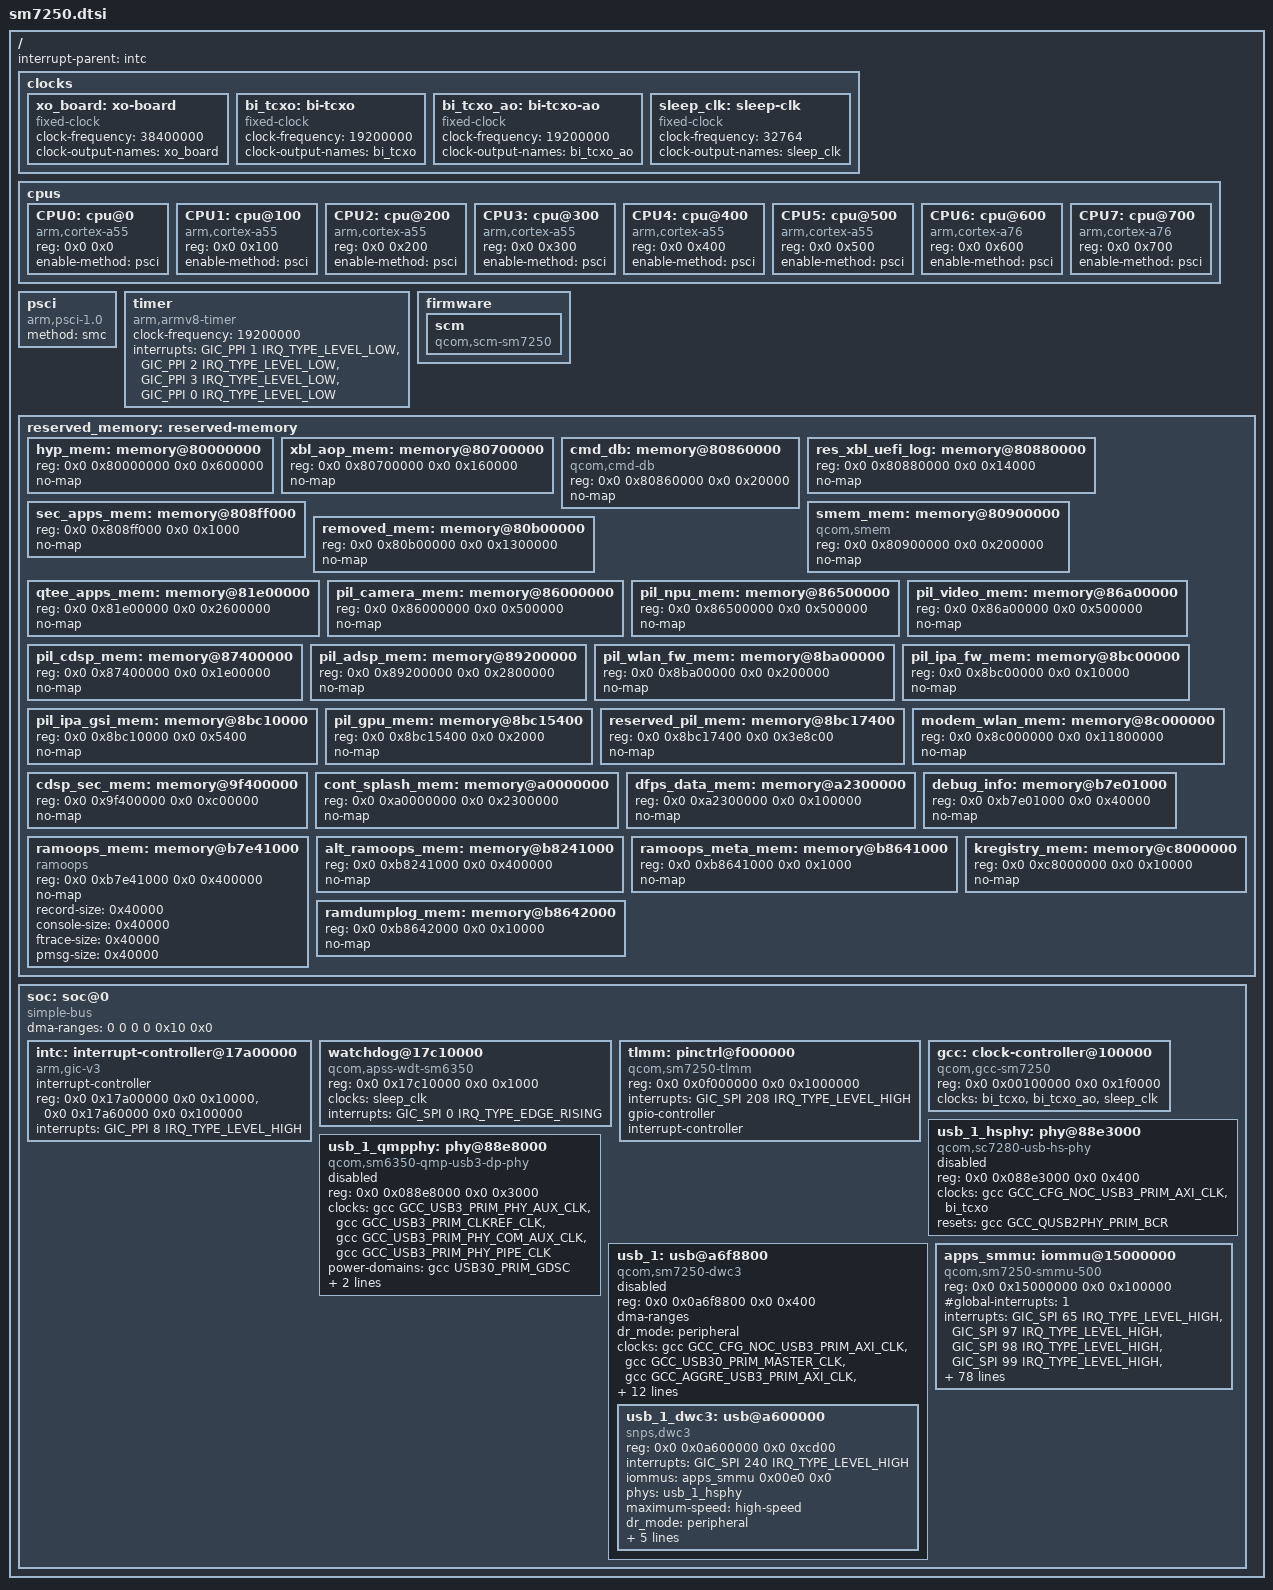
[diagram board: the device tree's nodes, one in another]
// SPDX-License-Identifier: BSD-3-Clause
/*
 * Copyright (c) 2026, Yurii Bishchuk
 * Base Device Tree Source for Qualcomm SM7250 (Snapdragon 765G / Lito)
 */

#include <dt-bindings/interrupt-controller/arm-gic.h>
#include <dt-bindings/clock/qcom,sm7250-gcc.h>
#include <dt-bindings/clock/qcom,rpmh.h>
#include <dt-bindings/power/qcom-rpmpd.h>
#include <dt-bindings/gpio/gpio.h>
#include <dt-bindings/phy/phy-qcom-qmp.h>

/ {
	interrupt-parent = <&intc>;
	#address-cells = <2>;
	#size-cells = <2>;

	clocks {
		xo_board: xo-board {
			compatible = "fixed-clock";
			#clock-cells = <0>;
			clock-frequency = <38400000>;
			clock-output-names = "xo_board";
		};

		bi_tcxo: bi-tcxo {
			compatible = "fixed-clock";
			#clock-cells = <0>;
			clock-frequency = <19200000>;
			clock-output-names = "bi_tcxo";
		};

		bi_tcxo_ao: bi-tcxo-ao {
			compatible = "fixed-clock";
			#clock-cells = <0>;
			clock-frequency = <19200000>;
			clock-output-names = "bi_tcxo_ao";
		};

		sleep_clk: sleep-clk {
			compatible = "fixed-clock";
			#clock-cells = <0>;
			clock-frequency = <32764>;
			clock-output-names = "sleep_clk";
		};
	};

	cpus {
		#address-cells = <2>;
		#size-cells = <0>;

		CPU0: cpu@0 {
			device_type = "cpu";
			compatible = "arm,cortex-a55";
			reg = <0x0 0x0>;
			enable-method = "psci";
		};

		CPU1: cpu@100 {
			device_type = "cpu";
			compatible = "arm,cortex-a55";
			reg = <0x0 0x100>;
			enable-method = "psci";
		};

		CPU2: cpu@200 {
			device_type = "cpu";
			compatible = "arm,cortex-a55";
			reg = <0x0 0x200>;
			enable-method = "psci";
		};

		CPU3: cpu@300 {
			device_type = "cpu";
			compatible = "arm,cortex-a55";
			reg = <0x0 0x300>;
			enable-method = "psci";
		};

		CPU4: cpu@400 {
			device_type = "cpu";
			compatible = "arm,cortex-a55";
			reg = <0x0 0x400>;
			enable-method = "psci";
		};

		CPU5: cpu@500 {
			device_type = "cpu";
			compatible = "arm,cortex-a55";
			reg = <0x0 0x500>;
			enable-method = "psci";
		};

		CPU6: cpu@600 {
			device_type = "cpu";
			compatible = "arm,cortex-a76";
			reg = <0x0 0x600>;
			enable-method = "psci";
		};

		CPU7: cpu@700 {
			device_type = "cpu";
			compatible = "arm,cortex-a76";
			reg = <0x0 0x700>;
			enable-method = "psci";
		};
	};

	psci {
		compatible = "arm,psci-1.0";
		method = "smc";
	};

	timer {
		compatible = "arm,armv8-timer";
		clock-frequency = <19200000>;
		interrupts = <GIC_PPI 1 IRQ_TYPE_LEVEL_LOW>,
			     <GIC_PPI 2 IRQ_TYPE_LEVEL_LOW>,
			     <GIC_PPI 3 IRQ_TYPE_LEVEL_LOW>,
			     <GIC_PPI 0 IRQ_TYPE_LEVEL_LOW>;
	};

	firmware {
		scm: scm {
			compatible = "qcom,scm-sm7250", "qcom,scm";
			#reset-cells = <1>;
		};
	};

	reserved_memory: reserved-memory {
		#address-cells = <2>;
		#size-cells = <2>;
		ranges;

		hyp_mem: memory@80000000 {
			reg = <0x0 0x80000000 0x0 0x600000>;
			no-map;
		};

		xbl_aop_mem: memory@80700000 {
			reg = <0x0 0x80700000 0x0 0x160000>;
			no-map;
		};

		cmd_db: memory@80860000 {
			compatible = "qcom,cmd-db";
			reg = <0x0 0x80860000 0x0 0x20000>;
			no-map;
		};

		res_xbl_uefi_log: memory@80880000 {
			reg = <0x0 0x80880000 0x0 0x14000>;
			no-map;
		};

		sec_apps_mem: memory@808ff000 {
			reg = <0x0 0x808ff000 0x0 0x1000>;
			no-map;
		};

		smem_mem: memory@80900000 {
			compatible = "qcom,smem";
			reg = <0x0 0x80900000 0x0 0x200000>;
			no-map;
		};

		removed_mem: memory@80b00000 {
			reg = <0x0 0x80b00000 0x0 0x1300000>;
			no-map;
		};

		qtee_apps_mem: memory@81e00000 {
			reg = <0x0 0x81e00000 0x0 0x2600000>;
			no-map;
		};

		pil_camera_mem: memory@86000000 {
			reg = <0x0 0x86000000 0x0 0x500000>;
			no-map;
		};

		pil_npu_mem: memory@86500000 {
			reg = <0x0 0x86500000 0x0 0x500000>;
			no-map;
		};

		pil_video_mem: memory@86a00000 {
			reg = <0x0 0x86a00000 0x0 0x500000>;
			no-map;
		};

		pil_cdsp_mem: memory@87400000 {
			reg = <0x0 0x87400000 0x0 0x1e00000>;
			no-map;
		};

		pil_adsp_mem: memory@89200000 {
			reg = <0x0 0x89200000 0x0 0x2800000>;
			no-map;
		};

		pil_wlan_fw_mem: memory@8ba00000 {
			reg = <0x0 0x8ba00000 0x0 0x200000>;
			no-map;
		};

		pil_ipa_fw_mem: memory@8bc00000 {
			reg = <0x0 0x8bc00000 0x0 0x10000>;
			no-map;
		};

		pil_ipa_gsi_mem: memory@8bc10000 {
			reg = <0x0 0x8bc10000 0x0 0x5400>;
			no-map;
		};

		pil_gpu_mem: memory@8bc15400 {
			reg = <0x0 0x8bc15400 0x0 0x2000>;
			no-map;
		};

		reserved_pil_mem: memory@8bc17400 {
			reg = <0x0 0x8bc17400 0x0 0x3e8c00>;
			no-map;
		};

		modem_wlan_mem: memory@8c000000 {
			reg = <0x0 0x8c000000 0x0 0x11800000>;
			no-map;
		};

		cdsp_sec_mem: memory@9f400000 {
			reg = <0x0 0x9f400000 0x0 0xc00000>;
			no-map;
		};

		cont_splash_mem: memory@a0000000 {
			reg = <0x0 0xa0000000 0x0 0x2300000>;
			no-map;
		};

		dfps_data_mem: memory@a2300000 {
			reg = <0x0 0xa2300000 0x0 0x100000>;
			no-map;
		};

		debug_info: memory@b7e01000 {
			reg = <0x0 0xb7e01000 0x0 0x40000>;
			no-map;
		};

		ramoops_mem: memory@b7e41000 {
			compatible = "ramoops";
			reg = <0x0 0xb7e41000 0x0 0x400000>;
			no-map;
			record-size = <0x40000>;
			console-size = <0x40000>;
			ftrace-size = <0x40000>;
			pmsg-size = <0x40000>;
		};

		alt_ramoops_mem: memory@b8241000 {
			reg = <0x0 0xb8241000 0x0 0x400000>;
			no-map;
		};

		ramoops_meta_mem: memory@b8641000 {
			reg = <0x0 0xb8641000 0x0 0x1000>;
			no-map;
		};

		ramdumplog_mem: memory@b8642000 {
			reg = <0x0 0xb8642000 0x0 0x10000>;
			no-map;
		};

		kregistry_mem: memory@c8000000 {
			reg = <0x0 0xc8000000 0x0 0x10000>;
			no-map;
		};
	};

	soc: soc@0 {
		#address-cells = <2>;
		#size-cells = <2>;
		ranges = <0 0 0 0 0x10 0x0>;
		dma-ranges = <0 0 0 0 0x10 0x0>;
		compatible = "simple-bus";

		intc: interrupt-controller@17a00000 {
			compatible = "arm,gic-v3";
			#interrupt-cells = <3>;
			interrupt-controller;
			reg = <0x0 0x17a00000 0x0 0x10000>,
			      <0x0 0x17a60000 0x0 0x100000>;
			interrupts = <GIC_PPI 8 IRQ_TYPE_LEVEL_HIGH>;
		};

		watchdog@17c10000 {
			compatible = "qcom,apss-wdt-sm6350", "qcom,kpss-wdt";
			reg = <0x0 0x17c10000 0x0 0x1000>;
			clocks = <&sleep_clk>;
			interrupts = <GIC_SPI 0 IRQ_TYPE_EDGE_RISING>;
			status = "okay";
		};

		tlmm: pinctrl@f000000 {
			compatible = "qcom,sm7250-tlmm";
			reg = <0x0 0x0f000000 0x0 0x1000000>;
			interrupts = <GIC_SPI 208 IRQ_TYPE_LEVEL_HIGH>;
			gpio-controller;
			#gpio-cells = <2>;
			interrupt-controller;
			#interrupt-cells = <2>;
		};

		gcc: clock-controller@100000 {
			compatible = "qcom,gcc-sm7250";
			reg = <0x0 0x00100000 0x0 0x1f0000>;
			clocks = <&bi_tcxo>, <&bi_tcxo_ao>, <&sleep_clk>;
			clock-names = "bi_tcxo", "bi_tcxo_ao", "sleep_clk";
			#clock-cells = <1>;
			#reset-cells = <1>;
			#power-domain-cells = <1>;
		};

		usb_1_hsphy: phy@88e3000 {
			compatible = "qcom,sc7280-usb-hs-phy", "qcom,usb-snps-hs-7nm-phy";
			reg = <0x0 0x088e3000 0x0 0x400>;
			#phy-cells = <0>;
			clocks = <&gcc GCC_CFG_NOC_USB3_PRIM_AXI_CLK>,
				 <&bi_tcxo>;
			clock-names = "cfg_ahb", "ref";
			resets = <&gcc GCC_QUSB2PHY_PRIM_BCR>;
			status = "disabled";
		};

		usb_1_qmpphy: phy@88e8000 {
			compatible = "qcom,sm6350-qmp-usb3-dp-phy";
			reg = <0x0 0x088e8000 0x0 0x3000>;

			clocks = <&gcc GCC_USB3_PRIM_PHY_AUX_CLK>,
				 <&gcc GCC_USB3_PRIM_CLKREF_CLK>,
				 <&gcc GCC_USB3_PRIM_PHY_COM_AUX_CLK>,
				 <&gcc GCC_USB3_PRIM_PHY_PIPE_CLK>;
			clock-names = "aux", "ref", "com_aux", "usb3_pipe";

			power-domains = <&gcc USB30_PRIM_GDSC>;

			resets = <&gcc GCC_USB3_PHY_PRIM_BCR>,
				 <&gcc GCC_USB3_DP_PHY_PRIM_BCR>;
			reset-names = "phy", "common";

			#clock-cells = <1>;
			#phy-cells = <1>;

			status = "disabled";
		};

		usb_1: usb@a6f8800 {
			compatible = "qcom,sm7250-dwc3", "qcom,dwc3";
			reg = <0x0 0x0a6f8800 0x0 0x400>;
			#address-cells = <2>;
			#size-cells = <2>;
			ranges;
			dma-ranges;
			dr_mode = "peripheral";

			clocks = <&gcc GCC_CFG_NOC_USB3_PRIM_AXI_CLK>,
				 <&gcc GCC_USB30_PRIM_MASTER_CLK>,
				 <&gcc GCC_AGGRE_USB3_PRIM_AXI_CLK>,
				 <&gcc GCC_USB30_PRIM_SLEEP_CLK>,
				 <&gcc GCC_USB30_PRIM_MOCK_UTMI_CLK>,
				 <&gcc GCC_USB3_PRIM_CLKREF_CLK>;
			clock-names = "cfg_noc",
				      "core",
				      "iface",
				      "sleep",
				      "mock_utmi",
				      "xo";

			assigned-clocks = <&gcc GCC_USB30_PRIM_MOCK_UTMI_CLK>,
					  <&gcc GCC_USB30_PRIM_MASTER_CLK>;
			assigned-clock-rates = <19200000>, <200000000>;

			resets = <&gcc GCC_USB30_PRIM_BCR>;
			power-domains = <&gcc USB30_PRIM_GDSC>;

			interrupts-extended = <&intc GIC_SPI 144 IRQ_TYPE_LEVEL_HIGH>;
			interrupt-names = "pwr_event";

			qcom,select-utmi-as-pipe-clk;

			status = "disabled";

			usb_1_dwc3: usb@a600000 {
				compatible = "snps,dwc3";
				reg = <0x0 0x0a600000 0x0 0xcd00>;
				interrupts = <GIC_SPI 240 IRQ_TYPE_LEVEL_HIGH>;
				iommus = <&apps_smmu 0x00e0 0x0>;
				phys = <&usb_1_hsphy>;
				phy-names = "usb2-phy";
				maximum-speed = "high-speed";
				dr_mode = "peripheral";
				tx-fifo-resize;
				snps,dis_u2_susphy_quirk;
				snps,dis_enblslpm_quirk;
				snps,dis-u1-entry-quirk;
				snps,dis-u2-entry-quirk;
			};
		};

		apps_smmu: iommu@15000000 {
			compatible = "qcom,sm7250-smmu-500", "qcom,smmu-500", "arm,mmu-500";
			reg = <0x0 0x15000000 0x0 0x100000>;
			#iommu-cells = <2>;
			#global-interrupts = <1>;
			interrupts = <GIC_SPI 65 IRQ_TYPE_LEVEL_HIGH>,
				     <GIC_SPI 97 IRQ_TYPE_LEVEL_HIGH>,
				     <GIC_SPI 98 IRQ_TYPE_LEVEL_HIGH>,
				     <GIC_SPI 99 IRQ_TYPE_LEVEL_HIGH>,
				     <GIC_SPI 100 IRQ_TYPE_LEVEL_HIGH>,
				     <GIC_SPI 101 IRQ_TYPE_LEVEL_HIGH>,
				     <GIC_SPI 102 IRQ_TYPE_LEVEL_HIGH>,
				     <GIC_SPI 103 IRQ_TYPE_LEVEL_HIGH>,
				     <GIC_SPI 104 IRQ_TYPE_LEVEL_HIGH>,
				     <GIC_SPI 105 IRQ_TYPE_LEVEL_HIGH>,
				     <GIC_SPI 106 IRQ_TYPE_LEVEL_HIGH>,
				     <GIC_SPI 107 IRQ_TYPE_LEVEL_HIGH>,
				     <GIC_SPI 108 IRQ_TYPE_LEVEL_HIGH>,
				     <GIC_SPI 109 IRQ_TYPE_LEVEL_HIGH>,
				     <GIC_SPI 110 IRQ_TYPE_LEVEL_HIGH>,
				     <GIC_SPI 111 IRQ_TYPE_LEVEL_HIGH>,
				     <GIC_SPI 112 IRQ_TYPE_LEVEL_HIGH>,
				     <GIC_SPI 113 IRQ_TYPE_LEVEL_HIGH>,
				     <GIC_SPI 114 IRQ_TYPE_LEVEL_HIGH>,
				     <GIC_SPI 115 IRQ_TYPE_LEVEL_HIGH>,
				     <GIC_SPI 116 IRQ_TYPE_LEVEL_HIGH>,
				     <GIC_SPI 117 IRQ_TYPE_LEVEL_HIGH>,
				     <GIC_SPI 118 IRQ_TYPE_LEVEL_HIGH>,
				     <GIC_SPI 181 IRQ_TYPE_LEVEL_HIGH>,
				     <GIC_SPI 182 IRQ_TYPE_LEVEL_HIGH>,
				     <GIC_SPI 183 IRQ_TYPE_LEVEL_HIGH>,
				     <GIC_SPI 184 IRQ_TYPE_LEVEL_HIGH>,
				     <GIC_SPI 179 IRQ_TYPE_LEVEL_HIGH>,
				     <GIC_SPI 186 IRQ_TYPE_LEVEL_HIGH>,
				     <GIC_SPI 187 IRQ_TYPE_LEVEL_HIGH>,
				     <GIC_SPI 188 IRQ_TYPE_LEVEL_HIGH>,
				     <GIC_SPI 189 IRQ_TYPE_LEVEL_HIGH>,
				     <GIC_SPI 190 IRQ_TYPE_LEVEL_HIGH>,
				     <GIC_SPI 191 IRQ_TYPE_LEVEL_HIGH>,
				     <GIC_SPI 192 IRQ_TYPE_LEVEL_HIGH>,
				     <GIC_SPI 315 IRQ_TYPE_LEVEL_HIGH>,
				     <GIC_SPI 316 IRQ_TYPE_LEVEL_HIGH>,
				     <GIC_SPI 317 IRQ_TYPE_LEVEL_HIGH>,
				     <GIC_SPI 318 IRQ_TYPE_LEVEL_HIGH>,
				     <GIC_SPI 319 IRQ_TYPE_LEVEL_HIGH>,
				     <GIC_SPI 320 IRQ_TYPE_LEVEL_HIGH>,
				     <GIC_SPI 321 IRQ_TYPE_LEVEL_HIGH>,
				     <GIC_SPI 322 IRQ_TYPE_LEVEL_HIGH>,
				     <GIC_SPI 323 IRQ_TYPE_LEVEL_HIGH>,
				     <GIC_SPI 324 IRQ_TYPE_LEVEL_HIGH>,
				     <GIC_SPI 325 IRQ_TYPE_LEVEL_HIGH>,
				     <GIC_SPI 326 IRQ_TYPE_LEVEL_HIGH>,
				     <GIC_SPI 327 IRQ_TYPE_LEVEL_HIGH>,
				     <GIC_SPI 328 IRQ_TYPE_LEVEL_HIGH>,
				     <GIC_SPI 329 IRQ_TYPE_LEVEL_HIGH>,
				     <GIC_SPI 330 IRQ_TYPE_LEVEL_HIGH>,
				     <GIC_SPI 331 IRQ_TYPE_LEVEL_HIGH>,
				     <GIC_SPI 332 IRQ_TYPE_LEVEL_HIGH>,
				     <GIC_SPI 333 IRQ_TYPE_LEVEL_HIGH>,
				     <GIC_SPI 334 IRQ_TYPE_LEVEL_HIGH>,
				     <GIC_SPI 335 IRQ_TYPE_LEVEL_HIGH>,
				     <GIC_SPI 336 IRQ_TYPE_LEVEL_HIGH>,
				     <GIC_SPI 337 IRQ_TYPE_LEVEL_HIGH>,
				     <GIC_SPI 338 IRQ_TYPE_LEVEL_HIGH>,
				     <GIC_SPI 339 IRQ_TYPE_LEVEL_HIGH>,
				     <GIC_SPI 340 IRQ_TYPE_LEVEL_HIGH>,
				     <GIC_SPI 341 IRQ_TYPE_LEVEL_HIGH>,
				     <GIC_SPI 342 IRQ_TYPE_LEVEL_HIGH>,
				     <GIC_SPI 343 IRQ_TYPE_LEVEL_HIGH>,
				     <GIC_SPI 344 IRQ_TYPE_LEVEL_HIGH>,
				     <GIC_SPI 345 IRQ_TYPE_LEVEL_HIGH>,
				     <GIC_SPI 395 IRQ_TYPE_LEVEL_HIGH>,
				     <GIC_SPI 396 IRQ_TYPE_LEVEL_HIGH>,
				     <GIC_SPI 397 IRQ_TYPE_LEVEL_HIGH>,
				     <GIC_SPI 398 IRQ_TYPE_LEVEL_HIGH>,
				     <GIC_SPI 399 IRQ_TYPE_LEVEL_HIGH>,
				     <GIC_SPI 400 IRQ_TYPE_LEVEL_HIGH>,
				     <GIC_SPI 401 IRQ_TYPE_LEVEL_HIGH>,
				     <GIC_SPI 402 IRQ_TYPE_LEVEL_HIGH>,
				     <GIC_SPI 403 IRQ_TYPE_LEVEL_HIGH>,
				     <GIC_SPI 404 IRQ_TYPE_LEVEL_HIGH>,
				     <GIC_SPI 405 IRQ_TYPE_LEVEL_HIGH>,
				     <GIC_SPI 406 IRQ_TYPE_LEVEL_HIGH>,
				     <GIC_SPI 407 IRQ_TYPE_LEVEL_HIGH>,
				     <GIC_SPI 408 IRQ_TYPE_LEVEL_HIGH>,
				     <GIC_SPI 409 IRQ_TYPE_LEVEL_HIGH>;
			dma-coherent;
		};
	};
};
